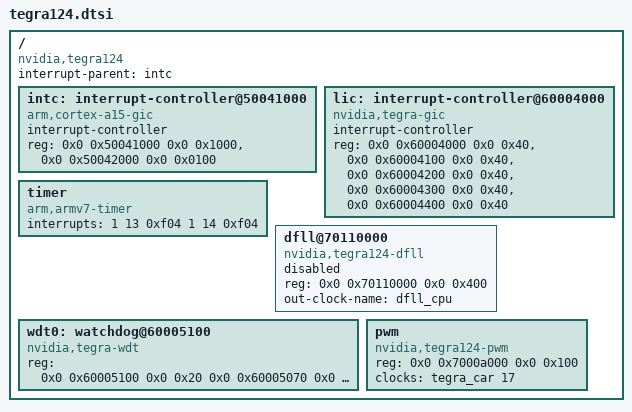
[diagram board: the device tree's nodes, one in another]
#include <dt-bindings/gpio/tegra-gpio.h>
#include <dt-bindings/input/input.h>
#include <dt-bindings/interrupt-controller/arm-gic.h>

/include/ "tegra124-soc.dtsi"

/ {
	compatible = "nvidia,tegra124";
	interrupt-parent = <&intc>;
	#address-cells = <2>;
	#size-cells = <2>;

	intc: interrupt-controller@50041000 {
		compatible = "arm,cortex-a15-gic";
		interrupt-controller;
		#interrupt-cells = <3>;
		reg = <0x0 0x50041000 0x0 0x1000>,
		      <0x0 0x50042000 0x0 0x0100>;
	};

	lic: interrupt-controller@60004000 {
		compatible = "nvidia,tegra-gic";
		interrupt-controller;
		reg = <0x0 0x60004000 0x0 0x40>,
		      <0x0 0x60004100 0x0 0x40>,
		      <0x0 0x60004200 0x0 0x40>,
		      <0x0 0x60004300 0x0 0x40>,
		      <0x0 0x60004400 0x0 0x40>;
        };

	timer {
		compatible = "arm,armv7-timer";
		interrupts = <1 13 0xf04
			      1 14 0xf04>;
	};

	dfll@70110000 {
			compatible = "nvidia,tegra124-dfll";
			reg = <0x0 0x70110000 0x0 0x400>;
			out-clock-name="dfll_cpu";
			status = "disabled";
	};

	/* WDT0 using TMR7 as timing reference */
	wdt0: watchdog@60005100 {
		compatible = "nvidia,tegra-wdt";
		reg = <0x0 0x60005100 0x0 0x20	/* WDT0 registers */
		0x0 0x60005070 0x0 0x8>;	/* TMR7 registers */
	};
	
	pwm: pwm {
			compatible = "nvidia,tegra124-pwm";
			reg = <0x0 0x7000a000 0x0 0x100>;
			#pwm-cells = <2>;
			clocks = <&tegra_car 17>;
			status = "okay";
	};
	
};
